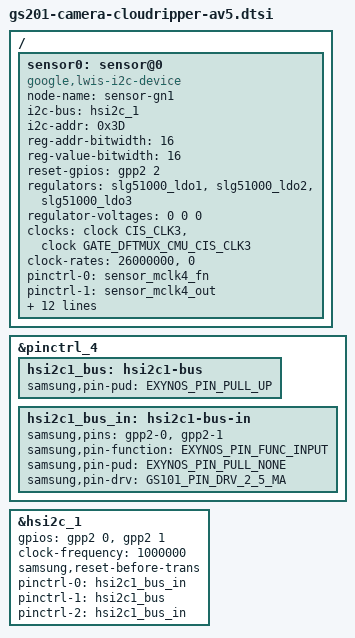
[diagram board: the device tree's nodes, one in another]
// SPDX-License-Identifier: GPL-2.0-only
/*
 * gs201 camera lwis device tree source for av5
 *
 * Copyright 2021 Google LLC.
 *
 */

#include <dt-bindings/clock/gs201.h>
#include <dt-bindings/gpio/gpio.h>
#include <dt-bindings/pinctrl/samsung.h>

&pinctrl_4 {
	hsi2c1_bus: hsi2c1-bus {
		samsung,pin-pud = <EXYNOS_PIN_PULL_UP>;
	};

	hsi2c1_bus_in: hsi2c1-bus-in {
		samsung,pins = "gpp2-0", "gpp2-1";
		samsung,pin-function = <EXYNOS_PIN_FUNC_INPUT>;
		samsung,pin-pud = <EXYNOS_PIN_PULL_NONE>;
		samsung,pin-drv = <GS101_PIN_DRV_2_5_MA>;
	};
 };

&hsi2c_1 {
	#address-cells = <1>;
	#size-cells = <0>;
	gpios = <&gpp2 0 GPIO_ACTIVE_HIGH &gpp2 1 GPIO_ACTIVE_HIGH>;
	status = "okay";
	clock-frequency = <1000000>;
	samsung,reset-before-trans;

	pinctrl-names = "default","on_i2c","off_i2c";
	pinctrl-0 = <&hsi2c1_bus_in>;
	pinctrl-1 = <&hsi2c1_bus>;
	pinctrl-2 = <&hsi2c1_bus_in>;
};

/ {
	fragment@lwiscamera {
		target-path = "/";
		__overlay__ {
			/* REAR CAMERA GN1 */
			sensor0: sensor@0 {
				compatible = "google,lwis-i2c-device";

				/* Device node name */
				node-name = "sensor-gn1";

				/* I2C */
				i2c-bus = <&hsi2c_1>;
				i2c-addr = <0x3D>;

				/* Registers */
				reg-addr-bitwidth = <16>;
				reg-value-bitwidth = <16>;

				/* GPIOs */
				/* CSID_RST_L GPP2[2] */
				reset-gpios = <&gpp2 2 GPIO_ACTIVE_HIGH>;

				/* Power sequence */
				regulators =
					<&slg51000_ldo1 &slg51000_ldo2
					 &slg51000_ldo3>;
				regulator-voltages =
					<0 0 0>;

				clocks =
					<&clock CIS_CLK3>,
					<&clock GATE_DFTMUX_CMU_CIS_CLK3>;
				clock-names =
					"CIS_CLK3",
					"GATE_DFTMUX_CMU_CIS_CLK3";
				clock-rates =
					<26000000>,
					<0>;

				/* MCLK Control */
				pinctrl-names = "mclk_on", "mclk_off";
				pinctrl-0 = <&sensor_mclk4_fn>;
				pinctrl-1 = <&sensor_mclk4_out>;

				/* Power up sequence */
				power-up-seqs =
					"ldo1",
					"ldo2",
					"ldo3",
					"reset",
					"mclk_on";
				power-up-seq-types =
					"regulator",
					"regulator",
					"regulator",
					"gpio",
					"pinctrl";
				power-up-seq-delays-us =
					<1000
					 1000
					 1000
					 1000
					 9000>;

				/* Power down sequence */
				power-down-seqs =
					"mclk_off",
					"reset",
					"ldo3",
					"ldo2",
					"ldo1";
				power-down-seq-types =
					"pinctrl",
					"gpio",
					"regulator",
					"regulator",
					"regulator";
				power-down-seq-delays-us =
					<1000
					 1000
					 2000
					 1000
					 1000>;
			};
		};
	};
};
